# MB9B160R register map
File version: 1.3
CPU: 
Registers are 8-bit, read-write, reset 0x0 unless marked. A register's access mark holds for its fields unless they carry their own. Offsets are from the block's base; [hi:lo] are bit positions.

## UNIQUE_ID
Base 0x40000200
0x00 UIDR0 32-bit ro — Unique ID Register 0
  [31:4] UID — Unique ID 27 through 0
0x04 UIDR1 32-bit ro — Unique ID Register 1
  [12:0] UID — Unique ID 40 through 28

## ECC_CAPTURE — ECC Capture Address
Base 0x40000300
0x00 FERRAD 32-bit ro — Flash ECC Error Address Capture Register
  [22:0] ERRAD — Flash ECC Error Address Capture

## CRTRIM — CR Trimming Registers
Base 0x4002E000
0x00 MCR_PSR reset 0x1 — High-speed CR oscillation Frequency Division Setup Register
  [2:0] CSR — High-speed CR oscillation frequency division ratio setting bits
0x04 MCR_FTRM 16-bit reset 0x1EF — High-speed CR oscillation Frequency Trimming Register
  [9:0] TRD — Frequency trimming setup bits
0x08 MCR_TTRM reset 0x10 — High-speed CR oscillation Temperature Trimming Register
  [4:0] TRT — Temperature trimming setup bits
0x0C MCR_RLR 32-bit reset 0x1 — High-Speed CR Oscillation Register Write-Protect Register
  [31:0] TRMLCK — Register write-protect bits

## SWWDT — Software Watchdog Timer
Base 0x40012000
0x00 WDOGLOAD 32-bit reset 0xFFFFFFFF — Software Watchdog Timer Load Register
0x04 WDOGVALUE 32-bit ro reset 0xFFFFFFFF — Software Watchdog Timer Value Register
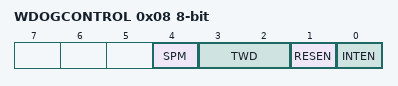
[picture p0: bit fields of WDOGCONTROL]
0x08 WDOGCONTROL — Software Watchdog Timer Control Register
  [4] SPM — Software Watchdog window watchdog mode enable bit
  [3:2] TWD — Timing window setting bit of the software watchdog
  [1] RESEN — Reset enable bit of the software watchdog
  [0] INTEN — Interrupt and counter enable bit of the software watchdog
0x0C WDOGINTCLR 32-bit reset 0xFFFFFFFF — Software Watchdog Timer Clear Register
0x10 WDOGRIS ro — Software Watchdog Timer Interrupt Status Register
  [0] RIS — Software watchdog interrupt status bit
0x18 WDOGSPMC — Software Watchdog Timer Window Watchdog Mode Control Register
  [0] TGR ro — Software watchdog trigger type bit
0xC00 WDOGLOCK 32-bit — Software Watchdog Timer Lock Register

## HWWDT — Hardware Watchdog Timer
Base 0x40011000
0x00 WDG_LDR 32-bit reset 0xFFFF — Hardware Watchdog Timer Load Register
0x04 WDG_VLR 32-bit ro — Hardware Watchdog Timer Value Register
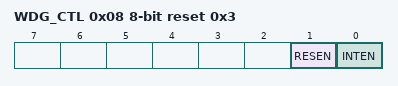
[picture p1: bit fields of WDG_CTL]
0x08 WDG_CTL reset 0x3 — Hardware Watchdog Timer Control Register
  [1] RESEN — Hardware watchdog reset enable bit
  [0] INTEN — Hardware watchdog interrupt and counter enable bit
0x0C WDG_ICL reset 0xFF (reset mask 0x0) — Hardware Watchdog Timer Clear Register
0x10 WDG_RIS ro reset 0xFF (reset mask 0x0) — Hardware Watchdog Timer Interrupt Status Register
  [0] RIS — Hardware watchdog interrupt status bit
0xC00 WDG_LCK 32-bit reset 0x1 — Hardware Watchdog Timer Lock Register

## DTIM — Dual Timer
Base 0x40015000
0x00 TIMER1LOAD 32-bit (DualTimer1 view) — Load Register
0x04 TIMER1VALUE 32-bit ro reset 0xFFFFFFFF — Value Register
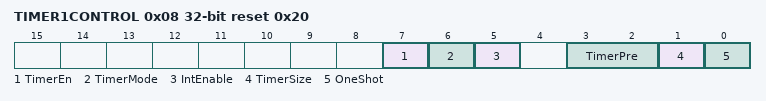
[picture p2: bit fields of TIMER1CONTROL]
0x08 TIMER1CONTROL 32-bit reset 0x20 — Control Register
  [7] TimerEn — Enable bit
  [6] TimerMode — Mode bit
  [5] IntEnable — Interrupt enable bit
  [3:2] TimerPre — Prescale bits
  [1] TimerSize — Counter size bit
  [0] OneShot — One-shot mode bit
0x0C TIMER1INTCLR 32-bit wo reset not defined — Interrupt Clear Register
0x10 TIMER1RIS 32-bit ro — Interrupt Status Register
  [0] TIMER1RIS — Interrupt Status Register bit
0x14 TIMER1MIS 32-bit ro — Masked Interrupt Status Register
  [0] TIMER1MIS — Masked Interrupt Status bit
0x18 TIMER1BGLOAD 32-bit — Background Load Register
0x20 TIMER2LOAD 32-bit reset not defined — Load Register
0x24 TIMER2VALUE 32-bit reset not defined — Value Register
0x28 TIMER2CONTROL 32-bit reset not defined — Control Register
0x2C TIMER2INTCLR 32-bit reset not defined — Interrupt Clear Register
0x30 TIMER2RIS 32-bit reset not defined — Interrupt Status Register
0x34 TIMER2MIS 32-bit reset not defined — Masked Interrupt Status Register
0x38 TIMER2BGLOAD 32-bit reset not defined — Background Load Register
